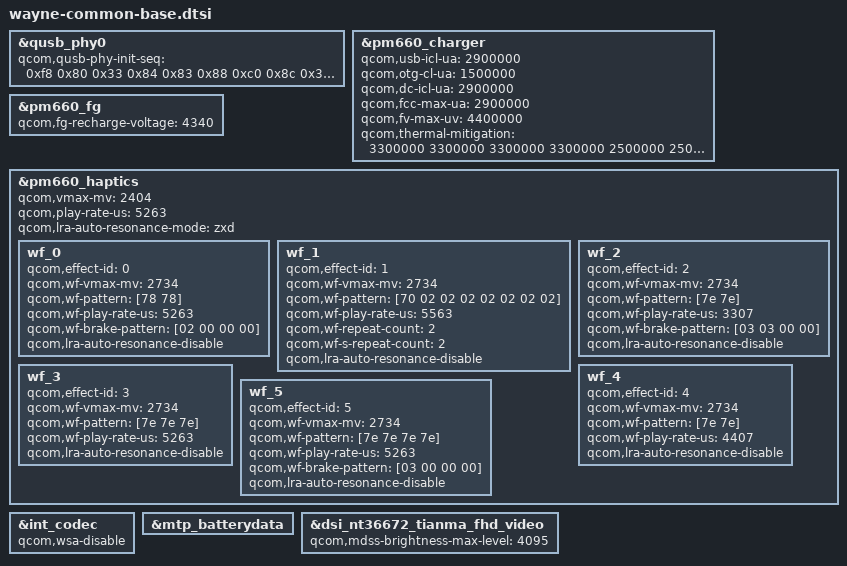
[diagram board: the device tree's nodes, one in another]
/* Copyright (c) 2019, The Linux Foundation. All rights reserved.
 *
 * This program is free software; you can redistribute it and/or modify
 * it under the terms of the GNU General Public License version 2 and
 * only version 2 as published by the Free Software Foundation.
 *
 * This program is distributed in the hope that it will be useful,
 * but WITHOUT ANY WARRANTY; without even the implied warranty of
 * MERCHANTABILITY or FITNESS FOR A PARTICULAR PURPOSE.  See the
 * GNU General Public License for more details.
 */
#include "wayne-camera-sensor-mtp.dtsi"
#include "sdm660-novatek-i2c_d2s.dtsi"

/* sdm660-common.dtsi diff wayne - whyred/tulip */
&qusb_phy0 {
	qcom,qusb-phy-init-seq = <0xf8 0x80
				0x33 0x84
				0x83 0x88
				0xc0 0x8c
				0x30 0x08
				0x79 0x0c
				0x21 0x10
				0x14 0x9c
				0x9f 0x1c
				0x00 0x18>;
};

&pm660_charger {
	qcom,usb-icl-ua = <2900000>;
	qcom,otg-cl-ua = <1500000>;
	qcom,dc-icl-ua = <2900000>;
	qcom,fcc-max-ua = <2900000>;
	qcom,fv-max-uv  = <4400000>;
	qcom,thermal-mitigation
			= <3300000 3300000 3300000 3300000 2500000 2500000 2100000>;
};

&pm660_fg {
	qcom,fg-recharge-voltage = <4340>;
};

&pm660_haptics {
	qcom,vmax-mv = <2404>;
	qcom,play-rate-us = <5263>;
	qcom,lra-auto-resonance-mode = "zxd";

	/delete-node/ wf_0;
	/delete-node/ wf_1;
	/delete-node/ wf_2;
	/delete-node/ wf_3;
	/delete-node/ wf_4;
	/delete-node/ wf_5;

	wf_0 {
		/* CLICK */
		qcom,effect-id = <0>;
		qcom,wf-vmax-mv = <2734>;
		qcom,wf-pattern = [78 78];
		qcom,wf-play-rate-us = <5263>;
		qcom,wf-brake-pattern = [02 00 00 00];
		qcom,lra-auto-resonance-disable;
	};
	wf_1 {
		/* DOUBLE CLICK */
		qcom,effect-id = <1>;
		qcom,wf-vmax-mv = <2734>;
		qcom,wf-pattern = [70 02 02 02 02 02 02 02];
		qcom,wf-play-rate-us = <5563>;
		qcom,wf-repeat-count = <2>;
		qcom,wf-s-repeat-count = <2>;
		qcom,lra-auto-resonance-disable;
	};
	wf_2 {
		/* TICK */
		qcom,effect-id = <2>;
		qcom,wf-vmax-mv = <2734>;
		qcom,wf-pattern = [7e 7e];
		qcom,wf-play-rate-us = <3307>;
		qcom,wf-brake-pattern = [03 03 00 00];
		qcom,lra-auto-resonance-disable;
	};
	wf_3 {
		/* THUD */
		qcom,effect-id = <3>;
		qcom,wf-vmax-mv = <2734>;
		qcom,wf-pattern = [7e 7e 7e];
		qcom,wf-play-rate-us = <5263>;
		qcom,lra-auto-resonance-disable;
	};
	wf_4 {
		/* POP */
		qcom,effect-id = <4>;
		qcom,wf-vmax-mv = <2734>;
		qcom,wf-pattern = [7e 7e];
		qcom,wf-play-rate-us = <4407>;
		qcom,lra-auto-resonance-disable;
	};
	wf_5 {
		/* HEAVY CLICK */
		qcom,effect-id = <5>;
		qcom,wf-vmax-mv = <2734>;
		qcom,wf-pattern = [7e 7e 7e 7e];
		qcom,wf-play-rate-us = <5263>;
		qcom,wf-brake-pattern = [03 00 00 00];
		qcom,lra-auto-resonance-disable;
	};
};

/* msm-audio.dtsi wayne specific diff */
&int_codec {
	qcom,wsa-disable;
	/delete-property/ qcom,msm-micbias2-ext-cap;
};

/* sdm660-mtp.dtsi wayne specific diff */
&mtp_batterydata {
	#include "fg-gen3-batterydata-l8866sun-3000mah.dtsi"
	#include "fg-gen3-batterydata-l8866cos-3000mah.dtsi"
	#include "fg-gen3-batterydata-l8866default-3000mah.dtsi"
};

&dsi_nt36672_tianma_fhd_video {
	qcom,mdss-brightness-max-level = <4095>;
};
